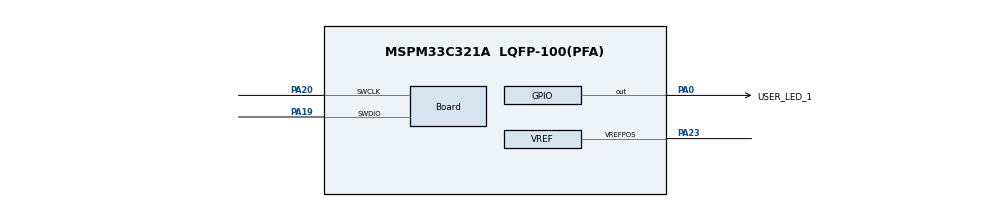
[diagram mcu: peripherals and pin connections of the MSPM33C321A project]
//@cliArgs --device "MSPM33C321A" --package "LQFP-100(PFA)" --part "Default"
//@v2CliArgs --device "MSPM33C321A" --package "LQFP-100(PFA)"
// @cliArgs --board /ti/boards/LP_MSPM33C321A --rtos nortos

/**
 * Import the modules used in this configuration.
 */
const Board         = scripting.addModule("/ti/driverlib/Board");
const COMP          = scripting.addModule("/ti/driverlib/COMP", {}, false);
const COMP1         = COMP.addInstance();
const GPIO          = scripting.addModule("/ti/driverlib/GPIO", {}, false);
const GPIO1         = GPIO.addInstance();
const SYSCTL        = scripting.addModule("/ti/driverlib/SYSCTL");
const VREF          = scripting.addModule("/ti/driverlib/VREF");
const ProjectConfig = scripting.addModule("/ti/project_config/ProjectConfig");

/**
 * Write custom configuration values to the imported modules.
 */
Board.InitPriority8               = "/ti/driverlib/VREF";
Board.peripheral.$assign          = "DEBUGSS";
Board.peripheral.swclkPin.$assign = "PA20";
Board.peripheral.swdioPin.$assign = "PA19";

COMP1.$name                          = "COMP";
COMP1.selectOutputFilter             = "DL_COMP_FILTER_DELAY_1200";
COMP1.enableOutputFilter             = true;
COMP1.channelEnable                  = ["NEG"];
COMP1.hysteresis                     = "DL_COMP_HYSTERESIS_30";
COMP1.vSource                        = "DL_COMP_REF_SOURCE_VDDA_DAC";
COMP1.controlSelect                  = "DL_COMP_DAC_CONTROL_SW";
COMP1.enabledInterrupts              = ["DL_COMP_INTERRUPT_OUTPUT_EDGE","DL_COMP_INTERRUPT_OUTPUT_EDGE_INV"];
COMP1.peripheral.$assign             = "COMP0";
COMP1.peripheral.compPinNeg0.$assign = "PA27";
COMP1.compPinNeg0Config.$name        = "ti_driverlib_gpio_GPIOPinGeneric1";

GPIO1.$name                          = "GPIO_LEDS";
GPIO1.port                           = "PORTA";
GPIO1.portSegment                    = "Lower";
GPIO1.associatedPins[0].$name        = "USER_LED_1";
GPIO1.associatedPins[0].assignedPin  = "0";
GPIO1.associatedPins[0].initialValue = "SET";
GPIO1.associatedPins[0].pin.$assign  = "PA0";

SYSCTL.peripheral.$assign = "SYSCTL";

VREF.basicIntVolt                  = "DL_VREF_BUFCONFIG_OUTPUT_2_5V";
VREF.advClockConfigEnable          = true;
VREF.advClkSrc                     = "DL_VREF_CLOCK_BUSCLK";
VREF.checkVREFReady                = true;
VREF.basicExtVolt                  = 2.5;
VREF.peripheral.$assign            = "VREF";
VREF.peripheral.vrefPosPin.$assign = "PA23";
VREF.vrefPosPinConfig.$name        = "ti_driverlib_gpio_GPIOPinGeneric0";

ProjectConfig.genLinker  = true;
ProjectConfig.genStartup = true;
ProjectConfig.genOpts    = true;
ProjectConfig.genLibs    = true;
